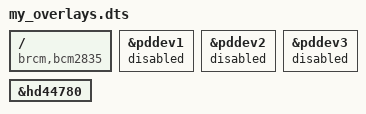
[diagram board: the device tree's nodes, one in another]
/dts-v1/;
/plugin/;

/ {
    compatible = "brcm,bcm2835";

    fragment@0 {
        target = <&pddev1>;
        __overlay__ {
            status = "disabled";
            };

        };
        
    fragment@1 {
        target = <&pddev2>;
        __overlay__ {
            status = "disabled";
            };

        };

    fragment@2 {
        target = <&pddev3>;
        __overlay__ {
            status = "disabled";
            };

        };

    fragment@3 {
        target = <&hd44780>;
        __overlay__ {
            status = "okay";
            };

        };
};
